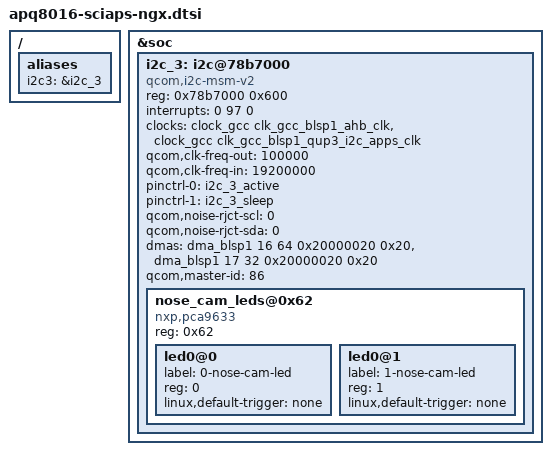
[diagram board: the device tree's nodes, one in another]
/* Copyright (c) 2015, The Linux Foundation. All rights reserved.
 *
 * This program is free software; you can redistribute it and/or modify
 * it under the terms of the GNU General Public License version 2 and
 * only version 2 as published by the Free Software Foundation.
 *
 * This program is distributed in the hope that it will be useful,
 * but WITHOUT ANY WARRANTY; without even the implied warranty of
 * MERCHANTABILITY or FITNESS FOR A PARTICULAR PURPOSE.  See the
 * GNU General Public License for more details.
 */

/ {
	aliases {
		i2c3 = &i2c_3; /* I2C3 controller device */
	};
};

&soc {
	i2c_3: i2c@78b7000 { /* BLSP1 QUP3 */
		compatible = "qcom,i2c-msm-v2";
		#address-cells = <1>;
		#size-cells = <0>;
		reg-names = "qup_phys_addr";
		reg = <0x78b7000 0x600>;
		interrupt-names = "qup_irq";
		interrupts = <0 97 0>;
		clocks = <&clock_gcc clk_gcc_blsp1_ahb_clk>,
			 <&clock_gcc clk_gcc_blsp1_qup3_i2c_apps_clk>;
		clock-names = "iface_clk", "core_clk";
		qcom,clk-freq-out = <100000>;
		qcom,clk-freq-in  = <19200000>;
		pinctrl-names = "i2c_active", "i2c_sleep";
		pinctrl-0 = <&i2c_3_active>;
		pinctrl-1 = <&i2c_3_sleep>;
		qcom,noise-rjct-scl = <0>;
		qcom,noise-rjct-sda = <0>;
		dmas = <&dma_blsp1 16 64 0x20000020 0x20>,
			<&dma_blsp1 17 32 0x20000020 0x20>;
		dma-names = "tx", "rx";
		qcom,master-id = <86>;
	};

	i2c@78b7000 { /* BLSP1 QUP3 */
		status = "ok";

		nose_cam_leds@0x62 {
			compatible = "nxp,pca9633";
			#address-cells = <1>;
			#size-cells = <0>;
			reg = <0x62>;
			//nxp,totem-pole;
			//nxp,change-on-ack;
			led0@0 {
				label = "0-nose-cam-led";
				reg = <0>;
				linux,default-trigger = "none";
			};
			led0@1 {
				label = "1-nose-cam-led";
				reg = <1>;
				linux,default-trigger = "none";
			};
		};
	};

};

